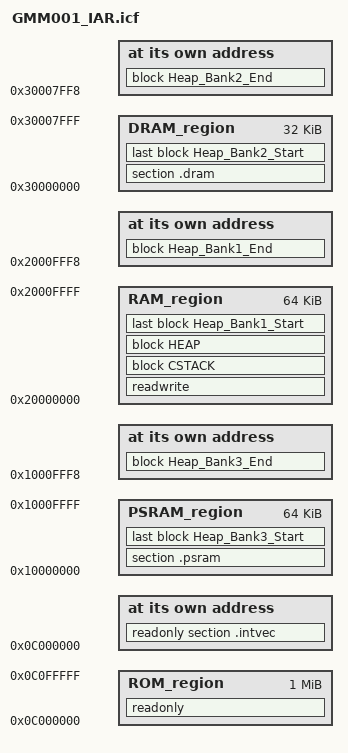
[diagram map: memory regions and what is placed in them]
/***********************************************************
*** IAR linkder configuration  file to demonstrate       *** 
*** GMM001 App requirements                              ***     
************************************************************

This file demonstrates the linker scatter file requirements for 
GMM001 App.

This file is a modified version of the default linker configuration
file avaiable in IAR Embedded Workbench.

The GMM001 App uses three memory banks for dynamic memory allocation.
Three memory banks are used due to three non-contiguos RAMs in XMC45xx 
devices. GMM001 App needs the start address and size of these banks.
These values shall be provided by the linker script.

We will attempt to use the avaialble free memory from each of DSRAM1,
DSRAM2 and PSRAM for these 3 banks.

Seems like linker config file logic does not allow dynamic size for heap.
Hence we use the following logic to get the boundaries of the Banks.
1. Define an empty block of 8 byte size at end of other allocations.
This allows dynamic shifting of the start of the Bank. The 'last' keyword
is used to make sure this block is at end of other allocations.
2. Define another block of 8 byte size at possible end of 
the Banks. This is a fixed address and normally equal to the 
end of the RAM. 
3. Apply __section_begin on the first block and __section_end on the
second block to get the boundaries. Derive the Bank size from these
boundaries.
4. For this purpose the following blocks are defined in this linker
configuration file
Heap_Bank1_Start
Heap_Bank1_End
Heap_Bank2_Start
Heap_Bank2_End
Heap_Bank3_Start
Heap_Bank3_End
 
IMPORTANT: Please always check the map file to ensure all memory
allocations are as intended and appropriate for your application.

Note: The default linker script uses some size for 'HEAP'. This is
harmless as long as 'HEAP' is not referred from application.
*/

/*###ICF### Section handled by ICF editor, don't touch! ****/
/*-Editor annotation file-*/
/* IcfEditorFile="$TOOLKIT_DIR$\config\ide\IcfEditor\cortex_v1_0.xml" */
/*-Specials-*/
define symbol __ICFEDIT_intvec_start__     = 0x0c000000;
/*-Memory Regions-*/
define symbol __ICFEDIT_region_ROM_start__ = 0x0c000000;
define symbol __ICFEDIT_region_ROM_end__   = 0x0c0FFFFF;
define symbol __ICFEDIT_region_RAM_start__ = 0x20000000;
define symbol __ICFEDIT_region_RAM_end__   = 0x2000FFFF;
/*-Sizes-*/
define symbol __ICFEDIT_size_cstack__      = 0x800;
define symbol __ICFEDIT_size_heap__        = 0x2000;
/**** End of ICF editor section. ###ICF###*/

define symbol __PSRAM_start__ = 0x10000000;
define symbol __PSRAM_end__   = 0x1000FFFF;

define symbol __DRAM_start__  = 0x30000000;
define symbol __DRAM_end__    = 0x30007FFF;

define memory mem with size = 4G;
define region ROM_region   = mem:[from __ICFEDIT_region_ROM_start__ to __ICFEDIT_region_ROM_end__];
define region RAM_region   = mem:[from __ICFEDIT_region_RAM_start__ to __ICFEDIT_region_RAM_end__];
define region PSRAM_region = mem:[from __PSRAM_start__ to __PSRAM_end__];
define region DRAM_region  = mem:[from __DRAM_start__  to __DRAM_end__ ];

define block CSTACK with alignment = 8, size = __ICFEDIT_size_cstack__{ };
define block HEAP   with alignment = 8, size = __ICFEDIT_size_heap__{ };

/*Define dummy blocks to find out the boundaries of available free
memory in each RAM regions*/
define block Heap_Bank1_Start with alignment = 8, size = 8 {};
define block Heap_Bank1_End with alignment = 8, size = 8 {};
define block Heap_Bank2_Start with alignment = 8, size = 8 {};
define block Heap_Bank2_End with alignment = 8, size = 8 {};
define block Heap_Bank3_Start with alignment = 8, size = 8 {};
define block Heap_Bank3_End with alignment = 8, size = 8 {};


initialize by copy {readwrite};
do not initialize  {section .noinit};

place at address mem:__ICFEDIT_intvec_start__ {readonly section .intvec};

place in ROM_region  {readonly};
place in RAM_region  {readwrite,
                      block CSTACK, block HEAP, 
					  /*place the dummy start block of Bank1 at the end 
					  of other allocations*/
					  last block Heap_Bank1_Start};
/*place the dummy end block of Bank1 at the end of the RAM region*/
place at address mem:(__ICFEDIT_region_RAM_end__ - 7) {block Heap_Bank1_End};
place in DRAM_region {section .dram, last block Heap_Bank2_Start};
place at address mem:(__DRAM_end__ - 7) {block Heap_Bank2_End};

place in PSRAM_region{section .psram, last block Heap_Bank3_Start};
place at address mem:(__PSRAM_end__ - 7) {block Heap_Bank3_End};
